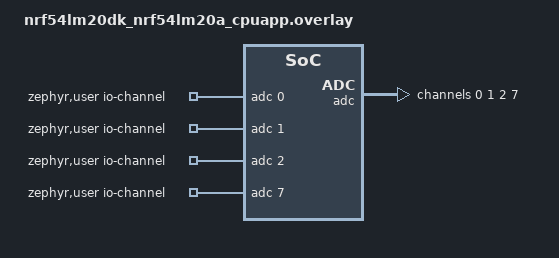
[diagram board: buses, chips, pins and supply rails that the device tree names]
/*
 * Copyright (c) 2025 Nordic Semiconductor ASA
 *
 * SPDX-License-Identifier: LicenseRef-Nordic-5-Clause
 */

/ {
	zephyr,user {
		io-channels = <&adc 0>, <&adc 1>, <&adc 2>, <&adc 7>;
	};
};

&adc {
	#address-cells = <1>;
	#size-cells = <0>;
	status = "okay";

	channel@0 {
		reg = <0>;
		zephyr,gain = "ADC_GAIN_1";
		zephyr,reference = "ADC_REF_INTERNAL";
		zephyr,acquisition-time = <ADC_ACQ_TIME_DEFAULT>;
		zephyr,input-positive = <NRF_SAADC_AIN4>; /* P1.06 */
		zephyr,resolution = <10>;
	};

	channel@1 {
		reg = <1>;
		zephyr,gain = "ADC_GAIN_1";
		zephyr,reference = "ADC_REF_INTERNAL";
		zephyr,acquisition-time = <ADC_ACQ_TIME_DEFAULT>;
		zephyr,input-positive = <NRF_SAADC_AIN2>; /* P1.30 */
		zephyr,resolution = <12>;
		zephyr,oversampling = <8>;
	};

	channel@2 {
		reg = <2>;
		zephyr,gain = "ADC_GAIN_1";
		zephyr,reference = "ADC_REF_INTERNAL";
		zephyr,acquisition-time = <ADC_ACQ_TIME_DEFAULT>;
		zephyr,input-positive = <NRF_SAADC_VDD>;
		zephyr,resolution = <12>;
		zephyr,oversampling = <8>;
	};

	channel@7 {
		reg = <7>;
		zephyr,gain = "ADC_GAIN_1";
		zephyr,reference = "ADC_REF_INTERNAL";
		zephyr,acquisition-time = <ADC_ACQ_TIME_DEFAULT>;
		zephyr,input-positive = <NRF_SAADC_AIN6>; /* P1.04 */
		zephyr,input-negative = <NRF_SAADC_AIN7>; /* P1.03 */
		zephyr,resolution = <12>;
	};
};
